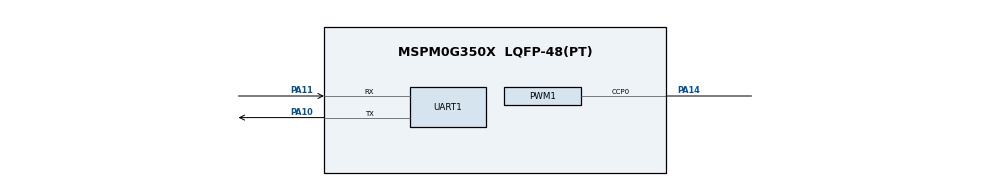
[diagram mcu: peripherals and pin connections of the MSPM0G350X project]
/**
 * @cliArgs --device "MSPM0G350X" --part "Default" --package "LQFP-48(PT)" --product "mspm0_sdk@2.05.01.00"
 * @versions {"tool":"1.24.0+4110"}
 */

/**
 * Import the modules used in this configuration.
 */
const Board   = scripting.addModule("/ti/driverlib/Board");
const GPIO    = scripting.addModule("/ti/driverlib/GPIO", {}, false);
const GPIO1   = GPIO.addInstance();
const PWM     = scripting.addModule("/ti/driverlib/PWM", {}, false);
const PWM1    = PWM.addInstance();
const SYSCTL  = scripting.addModule("/ti/driverlib/SYSCTL");
const SYSTICK = scripting.addModule("/ti/driverlib/SYSTICK");
const TIMER   = scripting.addModule("/ti/driverlib/TIMER", {}, false);
const TIMER1  = TIMER.addInstance();
const UART    = scripting.addModule("/ti/driverlib/UART", {}, false);
const UART1   = UART.addInstance();

/**
 * Write custom configuration values to the imported modules.
 */
const gate7  = system.clockTree["MFCLKGATE"];
gate7.enable = true;

Board.peripheral.$assign = "DEBUGSS";

GPIO1.$name                              = "KEY";
GPIO1.port                               = "PORTA";
GPIO1.associatedPins[0].$name            = "PIN_18";
GPIO1.associatedPins[0].direction        = "INPUT";
GPIO1.associatedPins[0].internalResistor = "PULL_DOWN";
GPIO1.associatedPins[0].assignedPin      = "18";
GPIO1.associatedPins[0].interruptEn      = true;
GPIO1.associatedPins[0].polarity         = "RISE";

PWM1.$name                      = "PWM_LED";
PWM1.clockDivider               = 8;
PWM1.timerStartTimer            = true;
PWM1.ccIndex                    = [0];
PWM1.peripheral.$assign         = "TIMG12";
PWM1.peripheral.ccp0Pin.$assign = "PA14";
PWM1.PWM_CHANNEL_0.$name        = "ti_driverlib_pwm_PWMTimerCC0";
PWM1.ccp0PinConfig.$name        = "ti_driverlib_gpio_GPIOPinGeneric2";

SYSCTL.forceDefaultClkConfig = true;
SYSCTL.clockTreeEn           = true;

SYSTICK.periodEnable      = true;
SYSTICK.period            = 32000;
SYSTICK.interruptEnable   = true;
SYSTICK.interruptPriority = "0";
SYSTICK.systickEnable     = true;

TIMER1.$name              = "TIMER_0";
TIMER1.timerClkDiv        = 8;
TIMER1.timerClkPrescale   = 100;
TIMER1.timerPeriod        = "1000 ms";
TIMER1.timerStartTimer    = true;
TIMER1.interrupts         = ["ZERO"];
TIMER1.timerMode          = "PERIODIC";
TIMER1.peripheral.$assign = "TIMG0";

UART1.$name                    = "UART_0";
UART1.uartClkSrc               = "MFCLK";
UART1.enabledInterrupts        = ["RX"];
UART1.peripheral.$assign       = "UART0";
UART1.peripheral.rxPin.$assign = "PA11";
UART1.peripheral.txPin.$assign = "PA10";
UART1.txPinConfig.$name        = "ti_driverlib_gpio_GPIOPinGeneric0";
UART1.rxPinConfig.$name        = "ti_driverlib_gpio_GPIOPinGeneric1";

const ProjectConfig              = scripting.addModule("/ti/project_config/ProjectConfig", {}, false);
ProjectConfig.migrationCondition = true;

/**
 * Pinmux solution for unlocked pins/peripherals. This ensures that minor changes to the automatic solver in a future
 * version of the tool will not impact the pinmux you originally saw.  These lines can be completely deleted in order to
 * re-solve from scratch.
 */
Board.peripheral.swclkPin.$suggestSolution   = "PA20";
Board.peripheral.swdioPin.$suggestSolution   = "PA19";
GPIO1.associatedPins[0].pin.$suggestSolution = "PA18";
